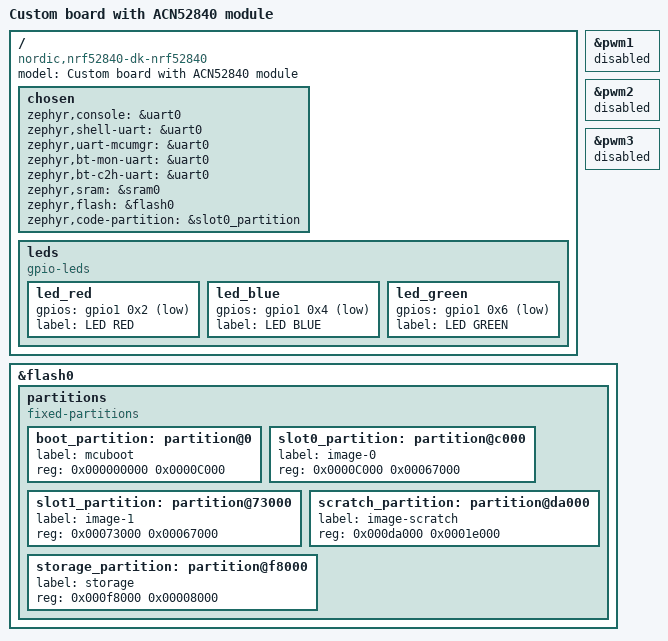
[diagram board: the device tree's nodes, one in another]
/dts-v1/;
#include <nordic/nrf52840_qiaa.dtsi>

/ {
	model = "Custom board with ACN52840 module";
	compatible = "nordic,nrf52840-dk-nrf52840";

	chosen {
		zephyr,console = &uart0;
		zephyr,shell-uart = &uart0;
		zephyr,uart-mcumgr = &uart0;
		zephyr,bt-mon-uart = &uart0;
		zephyr,bt-c2h-uart = &uart0;
		zephyr,sram = &sram0;
		zephyr,flash = &flash0;
		zephyr,code-partition = &slot0_partition;
	};

	leds {
		compatible = "gpio-leds";

		/* embedded RGB led */
		led_red {
			gpios = <&gpio1 0x2 GPIO_ACTIVE_LOW>;
			label = "LED RED";
		};
		led_blue {
			gpios = <&gpio1 0x4 GPIO_ACTIVE_LOW>;
			label = "LED BLUE";
		};
		led_green {
			gpios = <&gpio1 0x6 GPIO_ACTIVE_LOW>;
			label = "LED GREEN";
		};
	};
};

&pwm1 {
	status = "disabled";
};

&pwm2 {
	status = "disabled";
};

&pwm3 {
	status = "disabled";
};

&flash0 {
	partitions {
		compatible = "fixed-partitions";
		#address-cells = <1>;
		#size-cells = <1>;

		boot_partition: partition@0 {
			label = "mcuboot";
			reg = <0x000000000 0x0000C000>;
		};
		slot0_partition: partition@c000 {
			label = "image-0";
			reg = <0x0000C000 0x00067000>;
		};
		slot1_partition: partition@73000 {
			label = "image-1";
			reg = <0x00073000 0x00067000>;
		};
		scratch_partition: partition@da000 {
			label = "image-scratch";
			reg = <0x000da000 0x0001e000>;
		};

		/*
		 * The flash starting at 0x000f8000 and ending at
		 * 0x000fffff is reserved for use by the application.
		 */

		/*
		 * Storage partition will be used by FCB/LittleFS/NVS
		 * if enabled.
		 */
		storage_partition: partition@f8000 {
			label = "storage";
			reg = <0x000f8000 0x00008000>;
		};
	};
};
